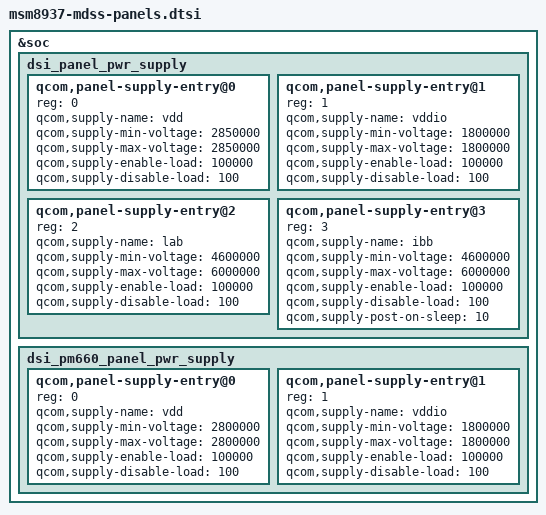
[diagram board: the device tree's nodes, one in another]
#include "dsi-panel-sim-video.dtsi"
#include "dsi-panel-sim-cmd.dtsi"
#include "dsi-panel-truly-1080p-video.dtsi"
#include "dsi-panel-truly-1080p-cmd.dtsi"
#include "dsi-panel-truly-720p-video.dtsi"
#include "dsi-panel-truly-720p-cmd.dtsi"
#include "dsi-panel-r69006-1080p-cmd.dtsi"
#include "dsi-panel-r69006-1080p-video.dtsi"
#include "dsi-panel-hx8394f-720p-video.dtsi"
#include "dsi-adv7533-1080p.dtsi"
#include "dsi-adv7533-720p.dtsi"
#include "dsi-panel-hx8399c-fhd-plus-video.dtsi"
#include "dsi-panel-hx8399c-hd-plus-video.dtsi"
#include "dsi-panel-nt35695b-truly-fhd-video.dtsi"
#include "dsi-panel-nt35695b-truly-fhd-cmd.dtsi"
#include "dsi-panel-icn9706-720-1440p-video.dtsi"
#include "dsi-panel-edo-rm67162-qvga-cmd.dtsi"

&soc {
	dsi_panel_pwr_supply: dsi_panel_pwr_supply {
		#address-cells = <1>;
		#size-cells = <0>;

		qcom,panel-supply-entry@0 {
			reg = <0>;
			qcom,supply-name = "vdd";
			qcom,supply-min-voltage = <2850000>;
			qcom,supply-max-voltage = <2850000>;
			qcom,supply-enable-load = <100000>;
			qcom,supply-disable-load = <100>;
		};

		qcom,panel-supply-entry@1 {
			reg = <1>;
			qcom,supply-name = "vddio";
			qcom,supply-min-voltage = <1800000>;
			qcom,supply-max-voltage = <1800000>;
			qcom,supply-enable-load = <100000>;
			qcom,supply-disable-load = <100>;
		};

		qcom,panel-supply-entry@2 {
			reg = <2>;
			qcom,supply-name = "lab";
			qcom,supply-min-voltage = <4600000>;
			qcom,supply-max-voltage = <6000000>;
			qcom,supply-enable-load = <100000>;
			qcom,supply-disable-load = <100>;
		};

		qcom,panel-supply-entry@3 {
			reg = <3>;
			qcom,supply-name = "ibb";
			qcom,supply-min-voltage = <4600000>;
			qcom,supply-max-voltage = <6000000>;
			qcom,supply-enable-load = <100000>;
			qcom,supply-disable-load = <100>;
			qcom,supply-post-on-sleep = <10>;
		};
	};

	dsi_pm660_panel_pwr_supply: dsi_pm660_panel_pwr_supply {
		#address-cells = <1>;
		#size-cells = <0>;

		qcom,panel-supply-entry@0 {
			reg = <0>;
			qcom,supply-name = "vdd";
			qcom,supply-min-voltage = <2800000>;
			qcom,supply-max-voltage = <2800000>;
			qcom,supply-enable-load = <100000>;
			qcom,supply-disable-load = <100>;
		};

		qcom,panel-supply-entry@1 {
			reg = <1>;
			qcom,supply-name = "vddio";
			qcom,supply-min-voltage = <1800000>;
			qcom,supply-max-voltage = <1800000>;
			qcom,supply-enable-load = <100000>;
			qcom,supply-disable-load = <100>;
		};
	};
};
